# ADuCM322i register map
Vendor: Analog Devices Inc.; Series: ARMCM3; File version: 1.0
CPU: CM3 r2p1, little endian, no MPU, no FPU, 3 interrupt priority bits
Registers are 16-bit, read-write, no defined reset value unless marked. A register's access mark holds for its fields unless they carry their own. Offsets are from the block's base; [hi:lo] are bit positions; {n}, {i} and the like mark numbered series.

## CLKCTL — Clock Gating and Other Settings
Base 0x40028000
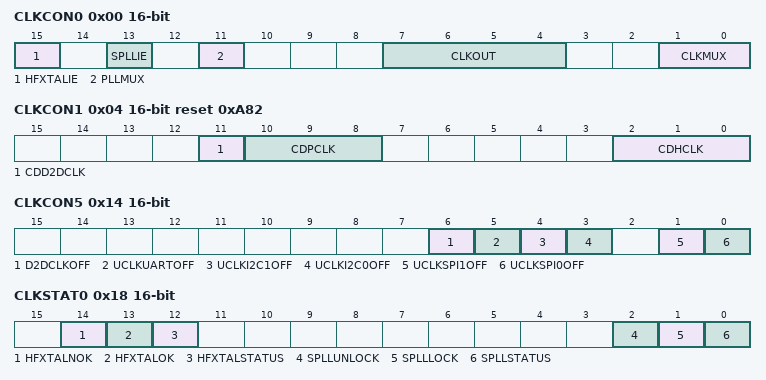
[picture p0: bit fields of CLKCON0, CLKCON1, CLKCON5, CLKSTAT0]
0x00 CLKCON0 — Misc clock settings register
  [15] HFXTALIE — High frequency crystal interrupt enable
    0=DIS (An interrupt to the core will not be generated on a HFXTAL ok or HFXTAL nok); 1=EN (An interrupt to the core will be generated on a HFXTAL ok or HFXTAL nok)
  [13] SPLLIE — SPLL Interrupt enable
    0=DIS (System PLL interrupt will not be generated); 1=EN (System PLL interrupt will be generated)
  [11] PLLMUX — PLL source selection
    0=HFOSC (Internal oscillator is selected (HFOSC)); 1=HFXTAL (External oscillator is selected (HFXTAL))
  [7:4] CLKOUT — GPIO clk out select
    0=ROOT (Root Clock); 1=LFOSC ((32 kHz)); 2=HFOSC ((16 MHz)); 4=CORE (Core Clock); 5=PCLK; 11=T0 (Timer 0 Clock); 12=WUT (Wake up Timer Clock); 14=HFXTAL
  [1:0] CLKMUX — Clock mux select
    0=HFOSC (High frequency internal oscillator (HFOSC)); 1=SPLL (System PLL is selected (80 MHz)); 2=UPLL (is selected (60 MHz)); 3=EXTCLK (External GPIO port is selected (ECLKIN))
0x04 CLKCON1 reset 0xA82 (reset mask 0x0) — Clock dividers register
  [11] CDD2DCLK ro — D2DCLK divide bits
    0=DIV1 (D2D_CLK frequency = HCLK frequency); 1=DIV2 (D2D_CLK frequency = half of HCLK frequency)
  [10:8] CDPCLK — PCLK divide bits
    0=DIV1 (Divide by 1 (PCLK is equal to root clock)); 1=DIV2 (Divide by 2 (PCLK is half the frequency of root clock)); 2=DIV4 (Divide by 4 (PCLK is quarter the frequency of root clock, 20 MHz)); 3=DIV8 (Divide by 8); 4=DIV16 (Divide by 16); 5=DIV32 (Divide by 32); 6=DIV64 (Divide by 164); 7=DIV128 (Divide by 128)
  [2:0] CDHCLK — HCLK divide bits
    0=DIV1 (Divide by 1 (HCLK is equal to root clock)); 1=DIV2 (Divide by 2 (HCLK is half the frequency of root clock)); 2=DIV4 (Divide by 4 (HCLK is quarter the frequency of root clock)); 3=DIV8 (Divide by 8); 4=DIV16 (Divide by 16); 5=DIV32 (Divide by 32); 6=DIV64 (Divide by 64); 7=DIV128 (Divide by 128)
0x14 CLKCON5 — User clock gating control register
  [all] fields
    0=ON (Clock on); 1=OFF (Clock off)
  [6] D2DCLKOFF — D2D clock user control
  [5] UCLKUARTOFF — UART clock user control
  [4] UCLKI2C1OFF — I2C1 clock user control
  [3] UCLKI2C0OFF — I2C0 clock user control
  [1] UCLKSPI1OFF — SPI1 clock user control
  [0] UCLKSPI0OFF — SPI0 clock user control
0x18 CLKSTAT0 — Clocking status
  [14] HFXTALNOK range 0x00000000..0x00000001 — HF crystal not stable
  [13] HFXTALOK range 0x00000000..0x00000001 — HF crystal stable
  [12] HFXTALSTATUS ro range 0x00000000..0x00000001 — HF crystal status
  [2] SPLLUNLOCK range 0x00000000..0x00000001 — System PLL unlock
  [1] SPLLLOCK range 0x00000000..0x00000001 — System PLL lock
  [0] SPLLSTATUS ro range 0x00000000..0x00000001 — System PLL status

## VDAC
Base 0x40082400
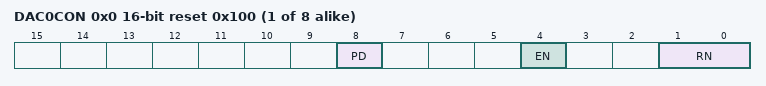
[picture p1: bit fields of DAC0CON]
{0x0+4i} DAC{i}CON reset 0x100 (reset mask 0x0) (i=0..7) — DAC{i} control register
  [8] PD range 0x00000000..0x00000001 — DAC{i} power down
  [4] EN range 0x00000000..0x00000001 — DAC{i} enable
  [1:0] RN range 0x00000000..0x00000003 — DAC{i} reference selection
{0x4004+4i} DAC{i}DAT 32-bit (i=0..7) — DAC{i} data register
  [27:16] DAT range 0x00000000..0x00000FFF — DAC{i} data

## InBuf — Input Buffer
Base 0x40081400
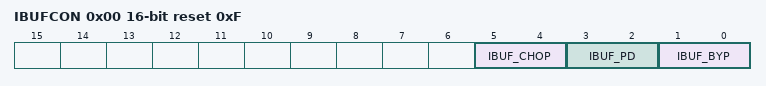
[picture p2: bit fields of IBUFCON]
0x00 IBUFCON reset 0xF (reset mask 0x0) — InBuf control register
  [5:4] IBUF_CHOP — CHOPINBUF enable the chop per InBuf separately
    0=OFF (Chopping disabled on both buffers.); 1=NSIDE (Chopping enabled on N-side only. P-side Disabled.); 2=PSIDE (Chopping enabled on P-side only. N-side Disabled.); 3=BOTH (Chopping enabled on both buffers.)
  [3:2] IBUF_PD — Power down P/N InBuf separately
    0=NONE (Both sides powered on); 1=NSIDE (only N side powered down); 2=PSIDE (only P side powered down); 3=BOTH (Both sides powered down)
  [1:0] IBUF_BYP — Bypass P/N InBuf seperately
    0=NONE (Bypass none sided); 1=NSIDE (N side bypassed); 2=PSIDE (P side bypassed); 3=BOTH (Bypass both)
